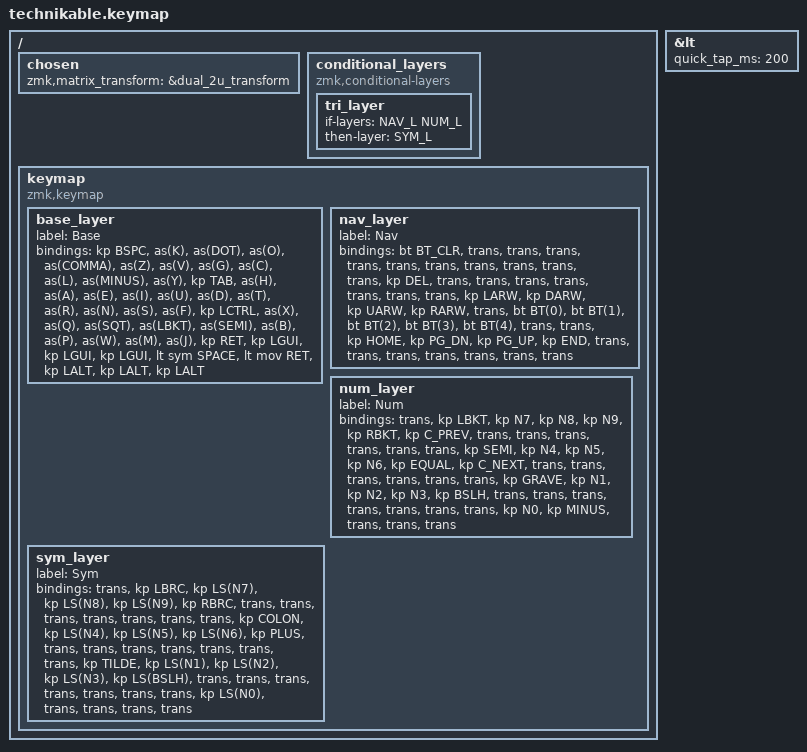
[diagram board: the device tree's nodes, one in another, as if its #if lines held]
/*
 * Copyright (c) 2022 Pete Johanson
 *
 * SPDX-License-Identifier: MIT
 */

#include <behaviors.dtsi>
#include <dt-bindings/zmk/keys.h>
#include <dt-bindings/zmk/bt.h>
#include <dt-bindings/zmk/outputs.h>

#define QWERTY_BASE 1

#define TBLE_ORTHO   true
// #define TBLE_MIT     true
// #define TBLE_DUAL_2U true

#define BAS_L 0
#define NAV_L 1
#define NUM_L 2
#define SYM_L 3

// Using layer taps on thumbs, having quick tap as well helps w/ repeating space/backspace
&lt { quick_tap_ms = <200>; };

#define BT(n) BT_SEL n

/ {
    chosen {
       zmk,matrix_transform =
#ifdef TBLE_DUAL_2U
                       &dual_2u_transform;
#elif defined(TBLE_MIT)
                       &mit_transform;
#else
                       &ortho_transform;
#endif
    };

    conditional_layers {
        compatible = "zmk,conditional-layers";
	tri_layer {
	    if-layers = <NAV_L NUM_L>;
	    then-layer = <SYM_L>;
	};
    };

    keymap {
        compatible = "zmk,keymap";

        base_layer {
            label = "Base";
			bindings = <
				&kp BSPC    &as(K)    &as(DOT)    &as(O)     &as(COMMA)       &as(Z)        &as(V)       &as(G)        &as(C)    &as(L)   &as(MINUS) &as(Y)
				&kp TAB     &as(H)    &as(A)      &as(E)     &as(I)           &as(U)        &as(D)       &as(T)        &as(R)    &as(N)   &as(S)     &as(F)
				&kp LCTRL   &as(X)    &as(Q)      &as(SQT)   &as(LBKT)        &as(SEMI)     &as(B)       &as(P)        &as(W)    &as(M)   &as(J)     &kp RET
				                      &kp LGUI    &kp LGUI   &kp LGUI  &lt sym SPACE &lt mov RET  &kp LALT  &kp LALT  &kp LALT  
			>;
        };

        nav_layer {
            label = "Nav";
            bindings = <
&bt BT_CLR &trans     &trans     &trans      &trans          &trans       &trans     &trans         &trans      &trans     &trans     &kp DEL
&trans     &trans     &trans     &trans      &trans          &trans       &trans     &kp LARW       &kp DARW    &kp UARW   &kp RARW   &trans
&bt BT(0)  &bt BT(1)  &bt BT(2) &bt BT(3)    &bt BT(4)       &trans       &trans     &kp HOME       &kp PG_DN   &kp PG_UP  &kp END    &trans
#ifdef TBLE_DUAL_2U
                      &trans     &trans              &trans                    &trans       &trans         &trans
#elif defined(TBLE_MIT)
                      &trans     &trans      &trans                &trans             &trans      &trans   &trans
#else
                      &trans     &trans      &trans          &trans       &trans    &trans  &trans         &trans
#endif
            >;
        };

        num_layer {
            label = "Num";
            bindings = <
&trans     &kp LBKT   &kp N7     &kp N8      &kp N9    &kp RBKT    &kp C_PREV    &trans         &trans       &trans       &trans     &trans
&trans     &kp SEMI   &kp N4     &kp N5      &kp N6    &kp EQUAL   &kp C_NEXT    &trans         &trans       &trans       &trans     &trans
&trans     &kp GRAVE  &kp N1     &kp N2      &kp N3    &kp BSLH    &trans        &trans         &trans       &trans       &trans     &trans
#ifdef TBLE_DUAL_2U
                     &trans     &kp N0              &kp MINUS                 &trans            &trans         &trans
#elif defined(TBLE_MIT)
                     &trans     &kp N0      &kp MINUS           &none            &kp ESC        &kp DEL      &trans
#else
                     &trans     &kp N0      &kp MINUS    &none         &none     &kp ESC        &kp DEL      &trans
#endif
            >;
        };

        sym_layer {
            label = "Sym";
            bindings = <
&trans     &kp LBRC   &kp LS(N7) &kp LS(N8)  &kp LS(N9)   &kp RBRC     &trans     &trans    &trans       &trans       &trans     &trans
&trans     &kp COLON  &kp LS(N4) &kp LS(N5)  &kp LS(N6)   &kp PLUS     &trans     &trans    &trans       &trans       &trans     &trans
&trans     &kp TILDE  &kp LS(N1) &kp LS(N2)  &kp LS(N3)   &kp LS(BSLH) &trans     &trans    &trans       &trans       &trans     &trans
#ifdef TBLE_DUAL_2U
                      &trans     &kp LS(N0)              &trans                    &trans       &trans         &trans
#elif defined(TBLE_MIT)
                      &trans     &kp LS(N0)      &trans                &trans             &trans      &trans   &trans
#else
                      &trans     &kp LS(N0)      &trans          &trans       &trans    &trans  &trans         &trans
#endif
            >;
        };

    };
};

